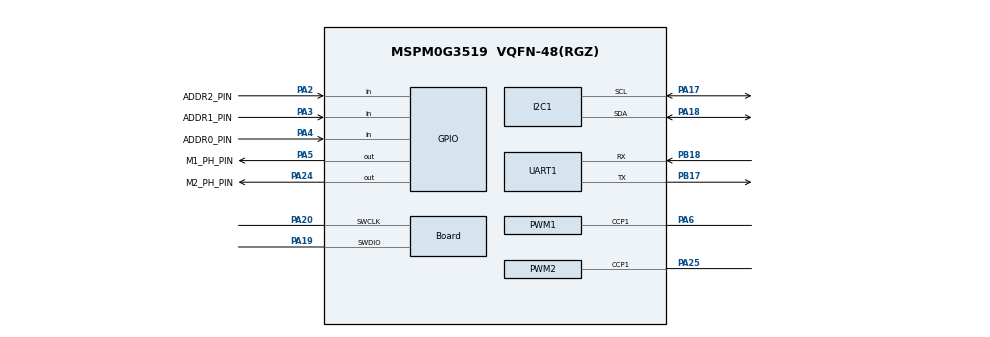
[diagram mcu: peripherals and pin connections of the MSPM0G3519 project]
/**
 * These arguments were used when this file was generated. They will be automatically applied on subsequent loads
 * via the GUI or CLI. Run CLI with '--help' for additional information on how to override these arguments.
 */
//@cliArgs --device "MSPM0G351X" --package "VQFN-48(RGZ)" --part "Default"
//@v2CliArgs --device "MSPM0G3519" --package "VQFN-48(RGZ)"
// @cliArgs --board /ti/boards/LP_MSPM0G3519 --rtos nortos

/**
 * Import the modules used in this configuration.
 */
const GPIO   = scripting.addModule("/ti/driverlib/GPIO", {}, false);
const GPIO1  = GPIO.addInstance();
const GPIO2  = GPIO.addInstance();
const GPIO3  = GPIO.addInstance();
const GPIO4  = GPIO.addInstance();
const GPIO5  = GPIO.addInstance();
const I2C    = scripting.addModule("/ti/driverlib/I2C", {}, false);
const I2C1   = I2C.addInstance();
const PWM    = scripting.addModule("/ti/driverlib/PWM", {}, false);
const PWM1   = PWM.addInstance();
const PWM2   = PWM.addInstance();
const SYSCTL = scripting.addModule("/ti/driverlib/SYSCTL");
const UART   = scripting.addModule("/ti/driverlib/UART", {}, false);
const UART1  = UART.addInstance();

/**
 * Write custom configuration values to the imported modules.
 */
SYSCTL.forceDefaultClkConfig = true;
SYSCTL.clockTreeEn           = true;

GPIO1.$name                          = "GPIO_M1_PH";
GPIO1.associatedPins[0].$name        = "M1_PH_PIN";
GPIO1.associatedPins[0].assignedPort = "PORTA";
GPIO1.associatedPins[0].assignedPin  = "5";
GPIO1.associatedPins[0].initialValue = "CLEARED";
GPIO1.associatedPins[0].pin.$assign  = "PA5";

GPIO2.$name                          = "GPIO_M2_PH";
GPIO2.associatedPins[0].$name        = "M2_PH_PIN";
GPIO2.associatedPins[0].assignedPort = "PORTA";
GPIO2.associatedPins[0].assignedPin  = "24";
GPIO2.associatedPins[0].initialValue = "CLEARED";
GPIO2.associatedPins[0].pin.$assign  = "PA24";

GPIO3.$name                              = "GPIO_ADDR0";
GPIO3.associatedPins[0].$name            = "ADDR0_PIN";
GPIO3.associatedPins[0].direction        = "INPUT";
GPIO3.associatedPins[0].assignedPort     = "PORTA";
GPIO3.associatedPins[0].assignedPin      = "4";
GPIO3.associatedPins[0].internalResistor = "PULL_UP";
GPIO3.associatedPins[0].pin.$assign      = "PA4";

GPIO4.$name                              = "GPIO_ADDR1";
GPIO4.associatedPins[0].$name            = "ADDR1_PIN";
GPIO4.associatedPins[0].direction        = "INPUT";
GPIO4.associatedPins[0].assignedPort     = "PORTA";
GPIO4.associatedPins[0].assignedPin      = "3";
GPIO4.associatedPins[0].internalResistor = "PULL_UP";
GPIO4.associatedPins[0].pin.$assign      = "PA3";

GPIO5.$name                              = "GPIO_ADDR2";
GPIO5.associatedPins[0].$name            = "ADDR2_PIN";
GPIO5.associatedPins[0].direction        = "INPUT";
GPIO5.associatedPins[0].assignedPort     = "PORTA";
GPIO5.associatedPins[0].assignedPin      = "2";
GPIO5.associatedPins[0].internalResistor = "PULL_UP";
GPIO5.associatedPins[0].pin.$assign      = "PA2";

I2C1.$name                     = "I2C_TARGET";
I2C1.basicEnableTarget         = true;
I2C1.basicTargetAddress        = 0x20;
I2C1.intTarget                 = ["START", "STOP", "RXFIFO_TRIGGER", "TXFIFO_TRIGGER"];
I2C1.peripheral.$assign        = "I2C1";
I2C1.peripheral.sclPin.$assign = "PA17";
I2C1.peripheral.sdaPin.$assign = "PA18";
I2C1.sclPinConfig.$name        = "I2C_TARGET_SCL";
I2C1.sclPinConfig.internalResistor = "PULL_UP";
I2C1.sdaPinConfig.$name        = "I2C_TARGET_SDA";
I2C1.sdaPinConfig.internalResistor = "PULL_UP";

PWM1.$name                      = "PWM_M1_EN";
PWM1.timerCount                 = 1600;
PWM1.peripheral.$assign         = "TIMG0";
PWM1.peripheral.ccp1Pin.$assign = "PA6";
PWM1.PWM_CHANNEL_1.$name        = "PWM_M1_EN_CHANNEL";
PWM1.PWM_CHANNEL_1.dutyCycle    = 0;

PWM2.$name                      = "PWM_M2_EN";
PWM2.timerCount                 = 1600;
PWM2.peripheral.$assign         = "TIMG12";
PWM2.peripheral.ccp1Pin.$assign = "PA25";
PWM2.PWM_CHANNEL_1.$name        = "PWM_M2_EN_CHANNEL";
PWM2.PWM_CHANNEL_1.dutyCycle    = 0;

UART1.$name                    = "UART_CONTROL";
UART1.rxFifoThreshold          = "DL_UART_RX_FIFO_LEVEL_ONE_ENTRY";
UART1.targetBaudRate           = 115200;
UART1.enableFIFO               = true;
UART1.txFifoThreshold          = "DL_UART_TX_FIFO_LEVEL_3_4_EMPTY";
UART1.enableDMARX              = false;
UART1.enableDMATX              = false;
UART1.enabledInterrupts        = ["RX"];
UART1.peripheral.rxPin.$assign = "PB18";
UART1.peripheral.txPin.$assign = "PB17";

const Board                       = scripting.addModule("/ti/driverlib/Board", {}, false);
Board.peripheral.$assign          = "DEBUGSS";
Board.peripheral.swclkPin.$assign = "PA20";
Board.peripheral.swdioPin.$assign = "PA19";

const ProjectConfig              = scripting.addModule("/ti/project_config/ProjectConfig", {}, false);
ProjectConfig.migrationCondition = true;
